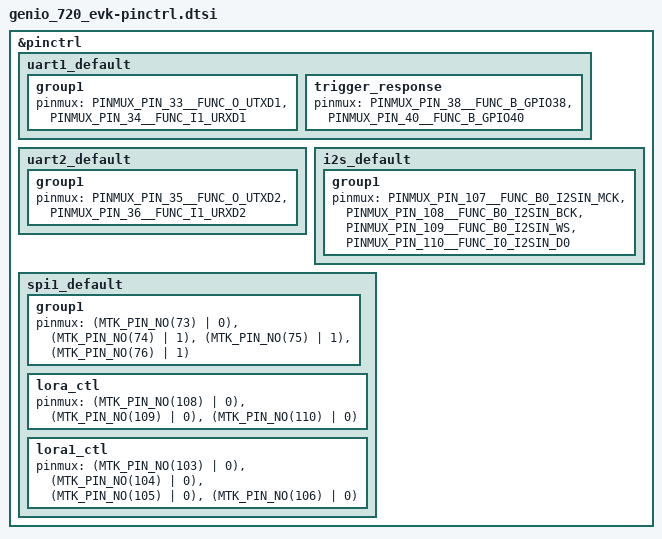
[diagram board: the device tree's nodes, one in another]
/*
 * Copyright (c) 2025 MediaTek
 *
 * SPDX-License-Identifier: Apache-2.0
 */

#include <dt-bindings/pinctrl/mt8391-pinctrl.h>
#include <zephyr/dt-bindings/pinctrl/mt8391-pinctrl.h>

&pinctrl {
	uart1_default: uart1_default {
		group1 {
			pinmux = <PINMUX_PIN_33__FUNC_O_UTXD1>,
					 <PINMUX_PIN_34__FUNC_I1_URXD1>;
		};

		trigger_response {
			pinmux = <PINMUX_PIN_38__FUNC_B_GPIO38>,
					 <PINMUX_PIN_40__FUNC_B_GPIO40>;
		};
	};

	/* UART2 -> Raspberry Pi HAT pins 8 (TX) / 10 (RX) with J470/J471 at 2-3. */
	uart2_default: uart2_default {
		group1 {
			pinmux = <PINMUX_PIN_35__FUNC_O_UTXD2>,
					 <PINMUX_PIN_36__FUNC_I1_URXD2>;
		};
	};

	i2s_default: i2s_default {
		group1 {
			pinmux = <PINMUX_PIN_107__FUNC_B0_I2SIN_MCK>,
					 <PINMUX_PIN_108__FUNC_B0_I2SIN_BCK>,
					 <PINMUX_PIN_109__FUNC_B0_I2SIN_WS>,
					 <PINMUX_PIN_110__FUNC_I0_I2SIN_D0>;
		};
	};

	/* SPI1 to the SX1262 LoRa radio 1. On this SoC pads 73-76 function 1
	 * are SPIM1 CSB/CLK/MOSI/MISO (mirrors the proven Linux devicetree;
	 * the generated macro header carries SPIM1 names on other pads, so
	 * raw pin/function values are used). Pad 73 stays function 0 (GPIO):
	 * chip select is software-driven via cs-gpios. Pads 108-110 are the
	 * radio control lines NRESET/BUSY/DIO1, function 0 (GPIO).
	 */
	spi1_default: spi1_default {
		group1 {
			pinmux = <(MTK_PIN_NO(73) | 0)>,
					 <(MTK_PIN_NO(74) | 1)>,
					 <(MTK_PIN_NO(75) | 1)>,
					 <(MTK_PIN_NO(76) | 1)>;
		};

		lora_ctl {
			pinmux = <(MTK_PIN_NO(108) | 0)>,
					 <(MTK_PIN_NO(109) | 0)>,
					 <(MTK_PIN_NO(110) | 0)>;
		};

		/* Radio 2 control lines DIO1/BUSY/NRESET/CS on pads 103-106,
		 * function 0 (GPIO); CS is software-driven via cs-gpios.
		 */
		lora1_ctl {
			pinmux = <(MTK_PIN_NO(103) | 0)>,
					 <(MTK_PIN_NO(104) | 0)>,
					 <(MTK_PIN_NO(105) | 0)>,
					 <(MTK_PIN_NO(106) | 0)>;
		};
	};
};
